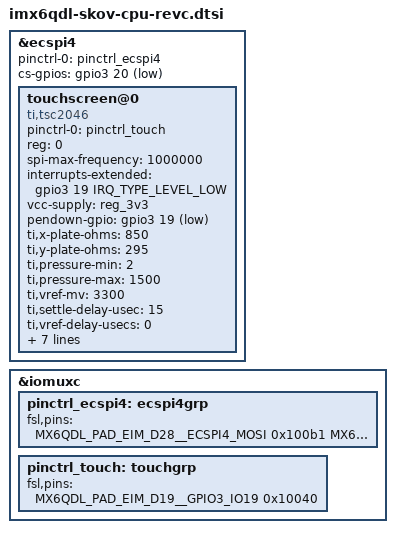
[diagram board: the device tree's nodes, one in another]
// SPDX-License-Identifier: (GPL-2.0 OR MIT)
//
// Copyright (C) 2020 Pengutronix, Ulrich Oelmann <kernel@pengutronix.de>

&ecspi4 {
	pinctrl-names = "default";
	pinctrl-0 = <&pinctrl_ecspi4>;
	cs-gpios = <&gpio3 20 GPIO_ACTIVE_LOW>;
	status = "okay";

	touchscreen@0 {
		pinctrl-names = "default";
		pinctrl-0 = <&pinctrl_touch>;
		compatible = "ti,tsc2046";
		reg = <0>;
		spi-max-frequency = <1000000>;
		interrupts-extended = <&gpio3 19 IRQ_TYPE_LEVEL_LOW>;
		vcc-supply = <&reg_3v3>;
		pendown-gpio = <&gpio3 19 GPIO_ACTIVE_LOW>;
		ti,x-plate-ohms = /bits/ 16 <850>;
		ti,y-plate-ohms = /bits/ 16 <295>;
		ti,pressure-min = /bits/ 16 <2>;
		ti,pressure-max = /bits/ 16 <1500>;
		ti,vref-mv = /bits/ 16 <3300>;
		ti,settle-delay-usec = /bits/ 16 <15>;
		ti,vref-delay-usecs = /bits/ 16 <0>;
		ti,penirq-recheck-delay-usecs = /bits/ 16 <100>;
		ti,debounce-max = /bits/ 16 <100>;
		ti,debounce-tol = /bits/ 16 <(~0)>;
		ti,debounce-rep = /bits/ 16 <4>;
		touchscreen-swapped-x-y;
		touchscreen-inverted-y;
		wakeup-source;
	};
};

&iomuxc {
	pinctrl_ecspi4: ecspi4grp {
		fsl,pins = <
			MX6QDL_PAD_EIM_D28__ECSPI4_MOSI			0x100b1
			MX6QDL_PAD_EIM_D22__ECSPI4_MISO			0x000b1
			MX6QDL_PAD_EIM_D21__ECSPI4_SCLK			0x000b1
			/* *no* external pull up */
			MX6QDL_PAD_EIM_D20__GPIO3_IO20		0x40000058
		>;
	};

	pinctrl_touch: touchgrp {
		fsl,pins = <
			/* external pull up */
			MX6QDL_PAD_EIM_D19__GPIO3_IO19			0x10040
		>;
	};
};
